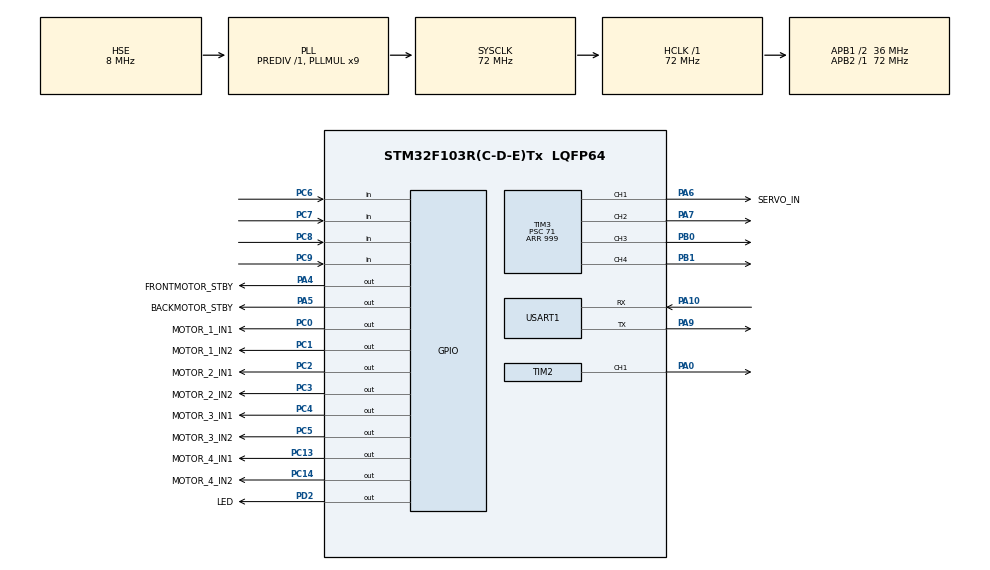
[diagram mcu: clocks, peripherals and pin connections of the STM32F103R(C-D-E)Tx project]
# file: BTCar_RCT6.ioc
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Mcu.Family=STM32F1
Mcu.Name=STM32F103R(C-D-E)Tx
Mcu.Package=LQFP64
NVIC.PriorityGroup=NVIC_PRIORITYGROUP_4
NVIC.TIM6_IRQn=true\:0\:0\:false\:false\:true\:true\:true\:true
NVIC.USART1_IRQn=true\:0\:0\:false\:false\:true\:true\:true\:true
PA0-WKUP.Signal=S_TIM2_CH1_ETR
PA10.Mode=Asynchronous
PA10.Signal=USART1_RX
PA4.GPIO_Label=FRONTMOTOR_STBY
PA4.Signal=GPIO_Output
PA5.GPIO_Label=BACKMOTOR_STBY
PA5.Signal=GPIO_Output
PA6.GPIO_Label=SERVO_IN
PA6.Signal=S_TIM3_CH1
PA7.Signal=S_TIM3_CH2
PA9.Mode=Asynchronous
PA9.Signal=USART1_TX
PB0.Signal=S_TIM3_CH3
PB1.Signal=S_TIM3_CH4
PC0.GPIO_Label=MOTOR_1_IN1
PC0.Signal=GPIO_Output
PC1.GPIO_Label=MOTOR_1_IN2
PC1.Signal=GPIO_Output
PC13-TAMPER-RTC.GPIO_Label=MOTOR_4_IN1
PC13-TAMPER-RTC.Signal=GPIO_Output
PC14-OSC32_IN.GPIO_Label=MOTOR_4_IN2
PC14-OSC32_IN.Signal=GPIO_Output
PC2.GPIO_Label=MOTOR_2_IN1
PC2.Signal=GPIO_Output
PC3.GPIO_Label=MOTOR_2_IN2
PC3.Signal=GPIO_Output
PC4.GPIO_Label=MOTOR_3_IN1
PC4.Signal=GPIO_Output
PC5.GPIO_Label=MOTOR_3_IN2
PC5.Signal=GPIO_Output
PC6.Signal=GPIO_Input
PC7.Signal=GPIO_Input
PC8.Signal=GPIO_Input
PC9.Signal=GPIO_Input
PD0-OSC_IN.Mode=HSE-External-Oscillator
PD0-OSC_IN.Signal=RCC_OSC_IN
PD1-OSC_OUT.Mode=HSE-External-Oscillator
PD1-OSC_OUT.Signal=RCC_OSC_OUT
PD2.GPIO_Label=LED
PD2.Signal=GPIO_Output
ProjectManager.HeapSize=0x200
ProjectManager.StackSize=0x400
ProjectManager.TargetToolchain=MDK-ARM V5.32
RCC.AHBFreq_Value=72000000
RCC.APB1CLKDivider=RCC_HCLK_DIV2
RCC.APB1Freq_Value=36000000
RCC.APB1TimFreq_Value=72000000
RCC.APB2Freq_Value=72000000
RCC.APB2TimFreq_Value=72000000
RCC.HCLKFreq_Value=72000000
RCC.PLLMUL=RCC_PLL_MUL9
RCC.PLLSourceVirtual=RCC_PLLSOURCE_HSE
RCC.SYSCLKFreq_VALUE=72000000
RCC.SYSCLKSource=RCC_SYSCLKSOURCE_PLLCLK
RCC.USBFreq_Value=72000000
SH.S_TIM2_CH1_ETR.0=TIM2_CH1,PWM Generation1 CH1
SH.S_TIM3_CH1.0=TIM3_CH1,PWM Generation1 CH1
SH.S_TIM3_CH2.0=TIM3_CH2,PWM Generation2 CH2
SH.S_TIM3_CH3.0=TIM3_CH3,PWM Generation3 CH3
SH.S_TIM3_CH4.0=TIM3_CH4,PWM Generation4 CH4
TIM2.Channel-PWM\ Generation1\ CH1=TIM_CHANNEL_1
TIM2.Period=1799
TIM2.Prescaler=799
TIM3.Channel-PWM\ Generation1\ CH1=TIM_CHANNEL_1
TIM3.Channel-PWM\ Generation2\ CH2=TIM_CHANNEL_2
TIM3.Channel-PWM\ Generation3\ CH3=TIM_CHANNEL_3
TIM3.Channel-PWM\ Generation4\ CH4=TIM_CHANNEL_4
TIM3.Period=999
TIM3.Prescaler=71
TIM6.AutoReloadPreload=TIM_AUTORELOAD_PRELOAD_ENABLE
TIM6.Period=9999
TIM6.Prescaler=7199
USART1.VirtualMode=VM_ASYNC
VP_SYS_VS_ND.Mode=No_Debug
VP_TIM2_VS_ClockSourceINT.Mode=Internal
VP_TIM3_VS_ClockSourceINT.Mode=Internal
VP_TIM6_VS_ClockSourceINT.Mode=Enable_Timer
board=custom

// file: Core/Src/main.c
/* USER CODE BEGIN Header */
/**
  ******************************************************************************
  * @file           : main.c
  * @brief          : Main program body
  ******************************************************************************
  * @attention
  *
  * Copyright (c) 2023 STMicroelectronics.
  * All rights reserved.
  *
  * This software is licensed under terms that can be found in the LICENSE file
  * in the root directory of this software component.
  * If no LICENSE file comes with this software, it is provided AS-IS.
  *
  ******************************************************************************
  */
/* USER CODE END Header */
#include "main.h"
#include "tim.h"
#include "usart.h"
#include "gpio.h"

/* USER CODE BEGIN Includes */
#include "Motor.h"
#include "Servo.h"
#include "CarMove.h"
#include <stdio.h>
/* USER CODE END Includes */

void SystemClock_Config(void);

/* USER CODE BEGIN 0 */
/*重写c库函数fputc,重定向printf*/
int fputc(int ch,FILE * f){
  HAL_UART_Transmit(&huart1,(uint8_t *)&ch,1,1000);
  return ch;
}
/* USER CODE END 0 */

int main(void)
{

  /* MCU Configuration--------------------------------------------------------*/

  /* Reset of all peripherals, Initializes the Flash interface and the Systick. */
  HAL_Init();

  /* Configure the system clock */
  SystemClock_Config();

  /* Initialize all configured peripherals */
  MX_GPIO_Init();
  MX_TIM2_Init();
  MX_TIM3_Init();
  MX_USART1_UART_Init();
  MX_TIM6_Init();
  /* USER CODE BEGIN 2 */

  Motor_Init();
  Servo_Init();

  printf("I can hear you\n");
  printf("CCR :%d\n",__HAL_TIM_GET_COMPARE(&htim2,TIM_CHANNEL_1));
  /* USER CODE END 2 */

  /* Infinite loop */
  while (1)
  {

    /* USER CODE BEGIN 3 */
    //LED现在由TIM6中断控制

    HAL_Delay(20);
    CarMove_FindLine();
  }
  /* USER CODE END 3 */
}

void SystemClock_Config(void)
{
  RCC_OscInitTypeDef RCC_OscInitStruct = {0};
  RCC_ClkInitTypeDef RCC_ClkInitStruct = {0};

  /** Initializes the RCC Oscillators according to the specified parameters
  * in the RCC_OscInitTypeDef structure.
  */
  RCC_OscInitStruct.OscillatorType = RCC_OSCILLATORTYPE_HSE;
  RCC_OscInitStruct.HSEState = RCC_HSE_ON;
  RCC_OscInitStruct.HSEPredivValue = RCC_HSE_PREDIV_DIV1;
  RCC_OscInitStruct.HSIState = RCC_HSI_ON;
  RCC_OscInitStruct.PLL.PLLState = RCC_PLL_ON;
  RCC_OscInitStruct.PLL.PLLSource = RCC_PLLSOURCE_HSE;
  RCC_OscInitStruct.PLL.PLLMUL = RCC_PLL_MUL9;
  if (HAL_RCC_OscConfig(&RCC_OscInitStruct) != HAL_OK)
  {
    Error_Handler();
  }

  /** Initializes the CPU, AHB and APB buses clocks
  */
  RCC_ClkInitStruct.ClockType = RCC_CLOCKTYPE_HCLK|RCC_CLOCKTYPE_SYSCLK
                              |RCC_CLOCKTYPE_PCLK1|RCC_CLOCKTYPE_PCLK2;
  RCC_ClkInitStruct.SYSCLKSource = RCC_SYSCLKSOURCE_PLLCLK;
  RCC_ClkInitStruct.AHBCLKDivider = RCC_SYSCLK_DIV1;
  RCC_ClkInitStruct.APB1CLKDivider = RCC_HCLK_DIV2;
  RCC_ClkInitStruct.APB2CLKDivider = RCC_HCLK_DIV1;

  if (HAL_RCC_ClockConfig(&RCC_ClkInitStruct, FLASH_LATENCY_2) != HAL_OK)
  {
    Error_Handler();
  }
}

void Error_Handler(void)
{
  __disable_irq();
  while (1)
  {
  }
}
